VERSION ""

NS_ :

BS_:

BU_: EngineControl

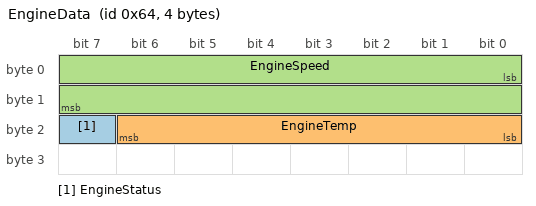
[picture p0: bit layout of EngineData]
BO_ 100 EngineData: 4 EngineControl
 SG_ EngineStatus : 23|1@1+ (1,0) [0|1] "" Vector__XXX
 SG_ EngineTemp : 16|7@1+ (1,0) [0|100] "degC" Vector__XXX
 SG_ EngineSpeed : 0|16@1+ (1,0) [0|5000] "RPM" Vector__XXX

BA_DEF_ SG_  "GenSigEnvVarType" ENUM  "int","float","undef";
BA_DEF_ SG_  "GenSigSendType" ENUM  "Cyclic","OnWrite","OnWriteWithRepetition","OnChange","OnChangeWithRepetition","IfActive","IfActiveWithRepetition";
BA_DEF_ BO_  "GenMsgSendType" ENUM  "Cyclic","not_used","not_used","not_used","not_used","Cyclic","not_used","IfActive";
BA_DEF_ BO_  "GenMsgCycleTime" INT 2 50000;
BA_DEF_ BO_  "GenMsgDelayTime" INT 1 1000;
BA_DEF_ BO_  "GenMsgCycleTimeFast" INT 2 50000;
BA_DEF_ BO_  "GenMsgILSupport" ENUM  "No","Yes";
BA_DEF_ BU_  "TpTxIdentifier" HEX 1536 1791;
BA_DEF_ BU_  "TpRxIdentifier" HEX 1536 1791;
BA_DEF_ BU_  "TpRxMask" HEX 0 255;
BA_DEF_ BU_  "TpCanBus" INT 0 2;
BA_DEF_ BU_  "TpUseFC" INT 0 1;
BA_DEF_ BU_  "TpNodeBaseAddress" HEX 0 33554431;
BA_DEF_ BU_  "ILUsed" ENUM  "Yes","No";
BA_DEF_  "GenEnvVarEndingDsp" STRING ;
BA_DEF_  "GenEnvVarEndingSnd" STRING ;
BA_DEF_  "GenEnvVarPrefix" STRING ;
BA_DEF_  "GenNWMTalkNM" STRING ;
BA_DEF_  "GenNWMGotoMode_BusSleep" STRING ;
BA_DEF_  "GenNWMGotoMode_Awake" STRING ;
BA_DEF_  "GenNWMApCanSleep" STRING ;
BA_DEF_  "GenNWMApCanOn" STRING ;
BA_DEF_  "GenNWMApCanOff" STRING ;
BA_DEF_  "NmBaseAddress" HEX 1280 1311;
BA_DEF_ BU_  "NodeLayerModules" STRING ;
BA_DEF_DEF_  "GenSigEnvVarType" "undef";
BA_DEF_DEF_  "GenSigSendType" "Cyclic";
BA_DEF_DEF_  "GenMsgSendType" "not_used";
BA_DEF_DEF_  "GenMsgCycleTime" 2;
BA_DEF_DEF_  "GenMsgDelayTime" 1;
BA_DEF_DEF_  "GenMsgCycleTimeFast" 100;
BA_DEF_DEF_  "GenMsgILSupport" "Yes";
BA_DEF_DEF_  "TpTxIdentifier" 1536;
BA_DEF_DEF_  "TpRxIdentifier" 1536;
BA_DEF_DEF_  "TpRxMask" 255;
BA_DEF_DEF_  "TpCanBus" 1;
BA_DEF_DEF_  "TpUseFC" 1;
BA_DEF_DEF_  "TpNodeBaseAddress" 1536;
BA_DEF_DEF_  "ILUsed" "Yes";
BA_DEF_DEF_  "GenEnvVarEndingDsp" "Dsp_";
BA_DEF_DEF_  "GenEnvVarEndingSnd" "_";
BA_DEF_DEF_  "GenEnvVarPrefix" "Env";
BA_DEF_DEF_  "GenNWMTalkNM" "TalkNM()";
BA_DEF_DEF_  "GenNWMGotoMode_BusSleep" "GotoMode_BusSleep()";
BA_DEF_DEF_  "GenNWMGotoMode_Awake" "GotoMode_Awake()";
BA_DEF_DEF_  "GenNWMApCanSleep" "apCanSleep()";
BA_DEF_DEF_  "GenNWMApCanOn" "apCanOn()";
BA_DEF_DEF_  "GenNWMApCanOff" "apCanOff()";
BA_DEF_DEF_  "NmBaseAddress" 1280;
BA_DEF_DEF_  "NodeLayerModules" "";
BA_ "NodeLayerModules" BU_ EngineControl "CANoeILNLVector.dll";
BA_ "GenMsgSendType" BO_ 100 0;
BA_ "GenMsgCycleTime" BO_ 100 10;
